CM_ "IMPORT _comma.dbc";
CM_ "IMPORT _honda_common.dbc";
CM_ "IMPORT _dual_nidec_common.dbc";
CM_ "IMPORT _steering_sensors_b.dbc";

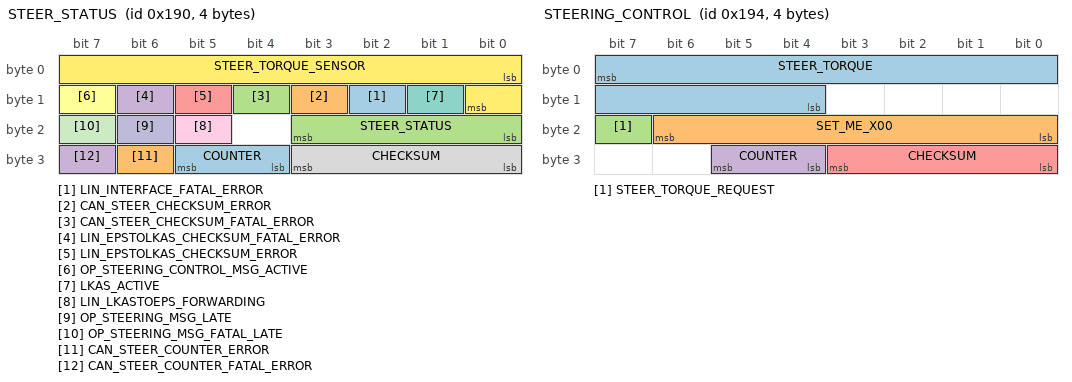
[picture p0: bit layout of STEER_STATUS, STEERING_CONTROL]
BO_ 400 STEER_STATUS: 4 EPS
 SG_ LIN_INTERFACE_FATAL_ERROR : 10|1@0+ (1,0) [0|1] "" XXX
 SG_ CAN_STEER_CHECKSUM_ERROR : 11|1@0+ (1,0) [0|1] "" XXX
 SG_ CAN_STEER_CHECKSUM_FATAL_ERROR : 12|1@0+ (1,0) [0|1] "" XXX
 SG_ LIN_EPSTOLKAS_CHECKSUM_FATAL_ERROR : 14|1@0+ (1,0) [0|1] "" XXX
 SG_ LIN_EPSTOLKAS_CHECKSUM_ERROR : 13|1@0+ (1,0) [0|1] "" XXX
 SG_ OP_STEERING_CONTROL_MSG_ACTIVE : 15|1@0+ (1,0) [0|1] "" XXX
 SG_ LKAS_ACTIVE : 9|1@0+ (1,0) [0|1] "" XXX
 SG_ CHECKSUM : 27|4@0+ (1,0) [0|3] "" EON
 SG_ LIN_LKASTOEPS_FORWARDING : 21|1@0+ (1,0) [0|1] "" XXX
 SG_ OP_STEERING_MSG_LATE : 22|1@0+ (1,0) [0|1] "" XXX
 SG_ OP_STEERING_MSG_FATAL_LATE : 23|1@0+ (1,0) [0|1] "" XXX
 SG_ STEER_TORQUE_SENSOR : 0|9@1- (1,0) [-256|256] "" XXX
 SG_ COUNTER : 29|2@0+ (1,0) [0|3] "" EON
 SG_ CAN_STEER_COUNTER_ERROR : 30|1@0+ (1,0) [0|1] "" XXX
 SG_ STEER_STATUS : 16|4@1+ (1,0) [0|15] "" XXX
 SG_ CAN_STEER_COUNTER_FATAL_ERROR : 31|1@0+ (1,0) [0|1] "" XXX

BO_ 404 STEERING_CONTROL: 4 EON
 SG_ STEER_TORQUE : 7|12@0- (1,0) [-768|768] "" EPS
 SG_ SET_ME_X00 : 22|7@0+ (1,0) [0|127] "" EPS
 SG_ STEER_TORQUE_REQUEST : 23|1@0+ (1,0) [0|1] "" EPS
 SG_ COUNTER : 29|2@0+ (1,0) [0|15] "" EPS
 SG_ CHECKSUM : 27|4@0+ (1,0) [0|3] "" EPS

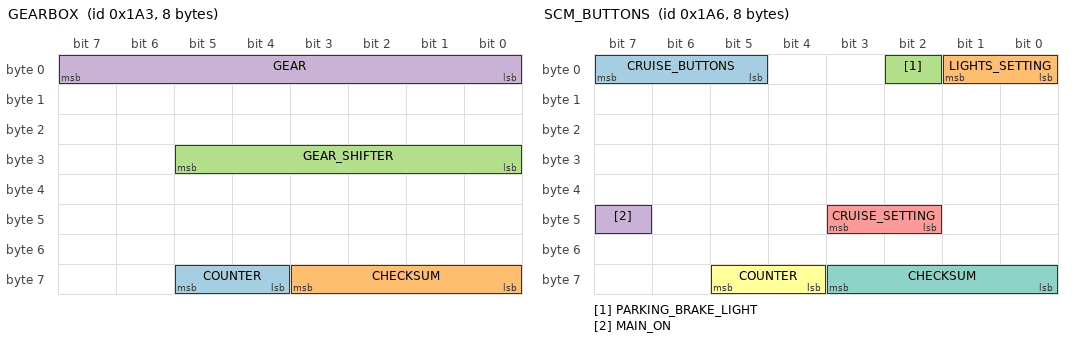
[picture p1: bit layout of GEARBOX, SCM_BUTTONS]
BO_ 419 GEARBOX: 8 PCM
 SG_ COUNTER : 61|2@0+ (1,0) [0|3] "" EON
 SG_ CHECKSUM : 59|4@0+ (1,0) [0|3] "" EON
 SG_ GEAR_SHIFTER : 29|6@0+ (1,0) [0|63] "" EON
 SG_ GEAR : 7|8@0+ (1,0) [0|255] "" EON

BO_ 422 SCM_BUTTONS: 8 SCM
 SG_ CRUISE_BUTTONS : 7|3@0+ (1,0) [0|7] "" EON
 SG_ LIGHTS_SETTING : 1|2@0+ (1,0) [0|3] "" EON
 SG_ PARKING_BRAKE_LIGHT : 2|1@0+ (1,0) [0|1] "" EON
 SG_ MAIN_ON : 47|1@0+ (1,0) [0|1] "" EON
 SG_ CRUISE_SETTING : 43|2@0+ (1,0) [0|3] "" EON
 SG_ COUNTER : 61|2@0+ (1,0) [0|3] "" EON
 SG_ CHECKSUM : 59|4@0+ (1,0) [0|15] "" EON

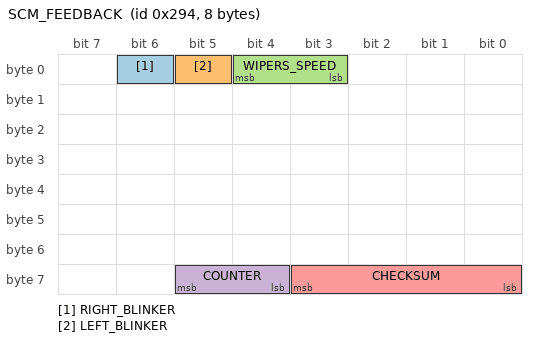
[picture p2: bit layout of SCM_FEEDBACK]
BO_ 660 SCM_FEEDBACK: 8 SCM
 SG_ RIGHT_BLINKER : 6|1@0+ (1,0) [0|1] "" EON
 SG_ LEFT_BLINKER : 5|1@0+ (1,0) [0|1] "" EON
 SG_ WIPERS_SPEED : 4|2@0+ (1,0) [0|3] "" EON
 SG_ COUNTER : 61|2@0+ (1,0) [0|3] "" EON
 SG_ CHECKSUM : 59|4@0+ (1,0) [0|15] "" EON

CM_ SG_ 422 PARKING_BRAKE_LIGHT "Believe this is just the dash light for the parking break";
VAL_ 400 STEER_STATUS 6 "tmp_fault" 5 "fault_1" 4 "no_torque_alert_2" 3 "low_speed_lockout" 2 "no_torque_alert_1" 0 "normal" ;
VAL_ 419 GEAR_SHIFTER 32 "D" 8 "R" 4 "P" ;
VAL_ 422 CRUISE_BUTTONS 7 "tbd" 6 "tbd" 5 "tbd" 4 "accel_res" 3 "decel_set" 2 "cancel" 1 "main" 0 "none" ;
